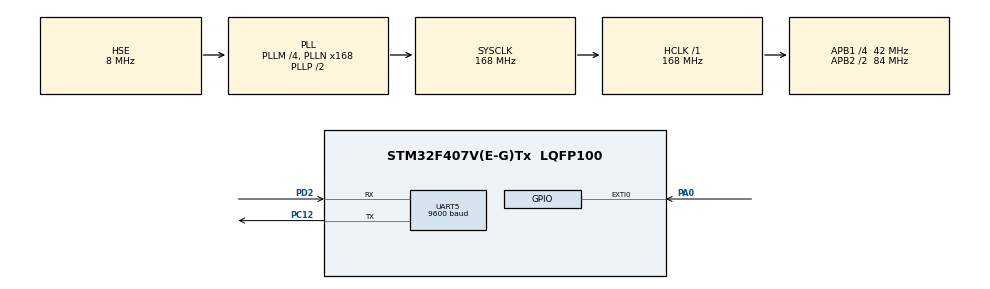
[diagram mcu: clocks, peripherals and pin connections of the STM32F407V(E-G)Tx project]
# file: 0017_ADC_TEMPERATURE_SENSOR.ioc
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ADC1.Channel-0\#ChannelRegularConversion=ADC_CHANNEL_VREFINT
ADC1.Channel-1\#ChannelRegularConversion=ADC_CHANNEL_TEMPSENSOR
ADC1.ContinuousConvMode=ENABLE
ADC1.NbrOfConversion=2
ADC1.NbrOfConversionFlag=1
ADC1.Rank-0\#ChannelRegularConversion=1
ADC1.Rank-1\#ChannelRegularConversion=2
ADC1.SamplingTime-0\#ChannelRegularConversion=ADC_SAMPLETIME_56CYCLES
ADC1.SamplingTime-1\#ChannelRegularConversion=ADC_SAMPLETIME_56CYCLES
ADC1.ScanConvMode=ENABLE
ADC1.master=1
Mcu.Family=STM32F4
Mcu.Name=STM32F407V(E-G)Tx
Mcu.Package=LQFP100
NVIC.ADC_IRQn=true\:0\:0\:false\:false\:true\:true\:true
NVIC.EXTI0_IRQn=true\:0\:0\:false\:false\:true\:true\:true
NVIC.PriorityGroup=NVIC_PRIORITYGROUP_4
PA0-WKUP.Signal=GPXTI0
PA13.Mode=Serial_Wire
PA13.Signal=SYS_JTMS-SWDIO
PA14.Mode=Serial_Wire
PA14.Signal=SYS_JTCK-SWCLK
PC12.Mode=Asynchronous
PC12.Signal=UART5_TX
PD2.Mode=Asynchronous
PD2.Signal=UART5_RX
PH0-OSC_IN.Mode=HSE-External-Oscillator
PH0-OSC_IN.Signal=RCC_OSC_IN
PH1-OSC_OUT.Mode=HSE-External-Oscillator
PH1-OSC_OUT.Signal=RCC_OSC_OUT
ProjectManager.HeapSize=0x200
ProjectManager.StackSize=0x400
ProjectManager.TargetToolchain=TrueSTUDIO
RCC.48MHZClocksFreq_Value=84000000
RCC.AHBFreq_Value=168000000
RCC.APB1CLKDivider=RCC_HCLK_DIV4
RCC.APB1Freq_Value=42000000
RCC.APB1TimFreq_Value=84000000
RCC.APB2CLKDivider=RCC_HCLK_DIV2
RCC.APB2Freq_Value=84000000
RCC.APB2TimFreq_Value=168000000
RCC.CortexFreq_Value=168000000
RCC.HCLKFreq_Value=168000000
RCC.HSE_VALUE=8000000
RCC.HSI_VALUE=16000000
RCC.LSE_VALUE=32768
RCC.PLLM=4
RCC.PLLN=168
RCC.PLLSourceVirtual=RCC_PLLSOURCE_HSE
RCC.SYSCLKFreq_VALUE=168000000
RCC.SYSCLKSource=RCC_SYSCLKSOURCE_PLLCLK
RCC.VCOOutputFreq_Value=336000000
UART5.BaudRate=9600
UART5.VirtualMode=Asynchronous
VP_ADC1_TempSens_Input.Mode=IN-TempSens
VP_ADC1_Vref_Input.Mode=IN-Vrefint
board=custom

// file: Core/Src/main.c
/* USER CODE BEGIN Header */
/**
  ******************************************************************************
  * @file           : main.c
  * @brief          : Main program body
  ******************************************************************************
  * @attention
  *
  * <h2><center>&copy; Copyright (c) 2021 STMicroelectronics.
  * All rights reserved.</center></h2>
  *
  * This software component is licensed by ST under BSD 3-Clause license,
  * the "License"; You may not use this file except in compliance with the
  * License. You may obtain a copy of the License at:
  *                        opensource.org/licenses/BSD-3-Clause
  *
  ******************************************************************************
  */
/* USER CODE END Header */
#include "main.h"

/* USER CODE BEGIN Includes */
#define VREFIN_CAL ((uint16_t*)((uint32_t)0x1FFF7A2A))
#define V25 (float) 0.76
#define Avg_slope (float) 0.0025

#include "stdio.h"
#include "string.h"
/* USER CODE END Includes */

/* USER CODE BEGIN PTD */
uint16_t adc1_value[2];
float Vsense=0, Vdda=0, Temperature=0;
int count=0;
char data[32]=" ";
/* USER CODE END PTD */

ADC_HandleTypeDef hadc1;

UART_HandleTypeDef huart5;

void SystemClock_Config(void);
static void MX_GPIO_Init(void);
static void MX_ADC1_Init(void);
static void MX_UART5_Init(void);

/* USER CODE BEGIN 0 */
void uprintf(char*data)
{
	HAL_UART_Transmit(&huart5, (uint8_t *)data, strlen(data), 100);
}

void HAL_GPIO_EXTI_Callback(uint16_t GPIO_Pin)
{
	sprintf(data,"\n\r Sicaklik = %f",Temperature);
	uprintf(data);
	Temperature = 0;
	HAL_ADC_Start_IT(&hadc1);
}

void HAL_ADC_ConvCpltCallback(ADC_HandleTypeDef* hadc)
{

		adc1_value[count] = HAL_ADC_GetValue(&hadc1);
		count++;

		/*
		 * count = 0 => Vrefint channel
		 * count = 1 => Temperature channel
		 */

		if (count==2)
		{
			count = 0;
		}

		Vdda = (float) 3.3 * (*VREFIN_CAL) / adc1_value[0];
		Vsense = Vdda * adc1_value[1] / 4095;

		Temperature = ((Vsense - V25) / Avg_slope) + 25;

}
/* USER CODE END 0 */

int main(void)
{

  /* MCU Configuration--------------------------------------------------------*/

  /* Reset of all peripherals, Initializes the Flash interface and the Systick. */
  HAL_Init();

  /* Configure the system clock */
  SystemClock_Config();

  /* Initialize all configured peripherals */
  MX_GPIO_Init();
  MX_ADC1_Init();
  MX_UART5_Init();
  /* USER CODE BEGIN 2 */
	  HAL_ADC_Start_IT(&hadc1);
  /* USER CODE END 2 */

  /* Infinite loop */
  while (1)
  {

  }
}

void SystemClock_Config(void)
{
  RCC_OscInitTypeDef RCC_OscInitStruct = {0};
  RCC_ClkInitTypeDef RCC_ClkInitStruct = {0};

  /** Configure the main internal regulator output voltage
  */
  __HAL_RCC_PWR_CLK_ENABLE();
  __HAL_PWR_VOLTAGESCALING_CONFIG(PWR_REGULATOR_VOLTAGE_SCALE1);
  /** Initializes the RCC Oscillators according to the specified parameters
  * in the RCC_OscInitTypeDef structure.
  */
  RCC_OscInitStruct.OscillatorType = RCC_OSCILLATORTYPE_HSE;
  RCC_OscInitStruct.HSEState = RCC_HSE_ON;
  RCC_OscInitStruct.PLL.PLLState = RCC_PLL_ON;
  RCC_OscInitStruct.PLL.PLLSource = RCC_PLLSOURCE_HSE;
  RCC_OscInitStruct.PLL.PLLM = 4;
  RCC_OscInitStruct.PLL.PLLN = 168;
  RCC_OscInitStruct.PLL.PLLP = RCC_PLLP_DIV2;
  RCC_OscInitStruct.PLL.PLLQ = 4;
  if (HAL_RCC_OscConfig(&RCC_OscInitStruct) != HAL_OK)
  {
    Error_Handler();
  }
  /** Initializes the CPU, AHB and APB buses clocks
  */
  RCC_ClkInitStruct.ClockType = RCC_CLOCKTYPE_HCLK|RCC_CLOCKTYPE_SYSCLK
                              |RCC_CLOCKTYPE_PCLK1|RCC_CLOCKTYPE_PCLK2;
  RCC_ClkInitStruct.SYSCLKSource = RCC_SYSCLKSOURCE_PLLCLK;
  RCC_ClkInitStruct.AHBCLKDivider = RCC_SYSCLK_DIV1;
  RCC_ClkInitStruct.APB1CLKDivider = RCC_HCLK_DIV4;
  RCC_ClkInitStruct.APB2CLKDivider = RCC_HCLK_DIV2;

  if (HAL_RCC_ClockConfig(&RCC_ClkInitStruct, FLASH_LATENCY_5) != HAL_OK)
  {
    Error_Handler();
  }
}

static void MX_ADC1_Init(void)
{

  ADC_ChannelConfTypeDef sConfig = {0};

  /** Configure the global features of the ADC (Clock, Resolution, Data Alignment and number of conversion)
  */
  hadc1.Instance = ADC1;
  hadc1.Init.ClockPrescaler = ADC_CLOCK_SYNC_PCLK_DIV4;
  hadc1.Init.Resolution = ADC_RESOLUTION_12B;
  hadc1.Init.ScanConvMode = ENABLE;
  hadc1.Init.ContinuousConvMode = ENABLE;
  hadc1.Init.DiscontinuousConvMode = DISABLE;
  hadc1.Init.ExternalTrigConvEdge = ADC_EXTERNALTRIGCONVEDGE_NONE;
  hadc1.Init.ExternalTrigConv = ADC_SOFTWARE_START;
  hadc1.Init.DataAlign = ADC_DATAALIGN_RIGHT;
  hadc1.Init.NbrOfConversion = 2;
  hadc1.Init.DMAContinuousRequests = DISABLE;
  hadc1.Init.EOCSelection = ADC_EOC_SINGLE_CONV;
  if (HAL_ADC_Init(&hadc1) != HAL_OK)
  {
    Error_Handler();
  }
  /** Configure for the selected ADC regular channel its corresponding rank in the sequencer and its sample time.
  */
  sConfig.Channel = ADC_CHANNEL_VREFINT;
  sConfig.Rank = 1;
  sConfig.SamplingTime = ADC_SAMPLETIME_56CYCLES;
  if (HAL_ADC_ConfigChannel(&hadc1, &sConfig) != HAL_OK)
  {
    Error_Handler();
  }
  /** Configure for the selected ADC regular channel its corresponding rank in the sequencer and its sample time.
  */
  sConfig.Channel = ADC_CHANNEL_TEMPSENSOR;
  sConfig.Rank = 2;
  if (HAL_ADC_ConfigChannel(&hadc1, &sConfig) != HAL_OK)
  {
    Error_Handler();
  }

}

static void MX_UART5_Init(void)
{

  huart5.Instance = UART5;
  huart5.Init.BaudRate = 9600;
  huart5.Init.WordLength = UART_WORDLENGTH_8B;
  huart5.Init.StopBits = UART_STOPBITS_1;
  huart5.Init.Parity = UART_PARITY_NONE;
  huart5.Init.Mode = UART_MODE_TX_RX;
  huart5.Init.HwFlowCtl = UART_HWCONTROL_NONE;
  huart5.Init.OverSampling = UART_OVERSAMPLING_16;
  if (HAL_UART_Init(&huart5) != HAL_OK)
  {
    Error_Handler();
  }

}

static void MX_GPIO_Init(void)
{
  GPIO_InitTypeDef GPIO_InitStruct = {0};

  /* GPIO Ports Clock Enable */
  __HAL_RCC_GPIOH_CLK_ENABLE();
  __HAL_RCC_GPIOA_CLK_ENABLE();
  __HAL_RCC_GPIOC_CLK_ENABLE();
  __HAL_RCC_GPIOD_CLK_ENABLE();

  /*Configure GPIO pin : PA0 */
  GPIO_InitStruct.Pin = GPIO_PIN_0;
  GPIO_InitStruct.Mode = GPIO_MODE_IT_RISING;
  GPIO_InitStruct.Pull = GPIO_NOPULL;
  HAL_GPIO_Init(GPIOA, &GPIO_InitStruct);

  /* EXTI interrupt init*/
  HAL_NVIC_SetPriority(EXTI0_IRQn, 0, 0);
  HAL_NVIC_EnableIRQ(EXTI0_IRQn);

}

void Error_Handler(void)
{
  __disable_irq();
  while (1)
  {
  }
}

/************************ (C) COPYRIGHT STMicroelectronics *****END OF FILE****/
